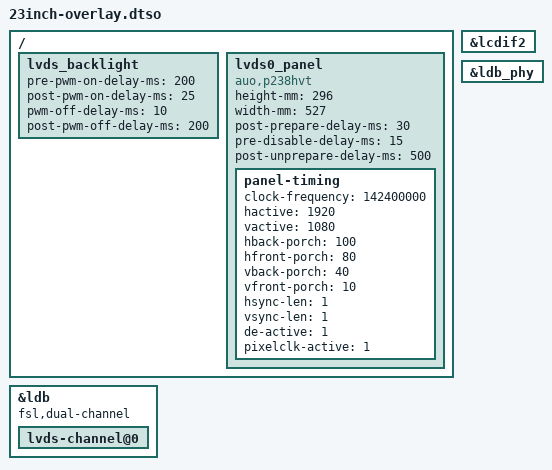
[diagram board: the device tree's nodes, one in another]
// SPDX-License-Identifier: (GPL-2.0+ OR MIT)
/*
 * Copyright 2023 ADLINK Technology Corp.
 *
 * Author: Po Cheng <po.cheng@adlinktech.com>
 */

/dts-v1/;
/plugin/;

/ {
	fragment@0 {
		target-path = "/";
		__overlay__ {
			lvds_backlight {
				pre-pwm-on-delay-ms = <200>;
				post-pwm-on-delay-ms = <25>;
				pwm-off-delay-ms = <10>;
				post-pwm-off-delay-ms = <200>;
				status = "okay";
			};
		};
	};

	fragment@1 {
		target-path = "/";
		__overlay__ {
			lvds0_panel {
				compatible = "auo,p238hvt", "panel-lvds";

				height-mm = <296>;
				width-mm = <527>;

				post-prepare-delay-ms = <30>;
				pre-disable-delay-ms = <15>;
				post-unprepare-delay-ms = <500>;

				status = "okay";

				panel-timing {
					clock-frequency = <142400000>;
					hactive = <1920>;
					vactive = <1080>;
					hback-porch = <100>;
					hfront-porch = <80>;
					vback-porch = <40>;
					vfront-porch = <10>;
					hsync-len = <1>;
					vsync-len = <1>;
					de-active = <1>;
					pixelclk-active = <1>;
				};
			};
		};
	};

	fragment@2 {
		target = <&ldb>;
		__overlay__ {
			fsl,dual-channel;
			status = "okay";
			lvds-channel@0 {
				status = "okay";
			};
		};
	};

	fragment@3 {
		target = <&lcdif2>;
		__overlay__ {
			status = "okay";
		};
	};

	fragment@4 {
		target = <&ldb_phy>;
		__overlay__ {
			status = "okay";
		};
	};
};

